# HPM6750 register map
Vendor: HPMICRO; Series: HPM6700/HPM6400; File version: 1.0
HPM6700/HPM6400 device
Registers are 32-bit, access not given, reset 0x0 unless marked. A register's access mark holds for its fields unless they carry their own. Offsets are from the block's base; lines under a group give offsets from that group; [hi:lo] are bit positions; {n}, {i} and the like mark numbered series; 'fields as' and 'values as' point back to an identical list; <NAME> marks a mode.

## Memory map
0xF4040000 IOC size 0xF64 — Input/Output Control
0xF40D8000 PIOC size 0xF64 — Power domain Input/Output Control
0xF5010000 BIOC size 0xF64 — Backup domain Input/Output Control

## IOC — Input/Output Control
Base 0xF4040000
Same registers: PIOC 0xF40D8000, BIOC 0xF5010000
{0x0+8i} pad_a[{i}] (i=0..31) group — Controller for input/output pad A
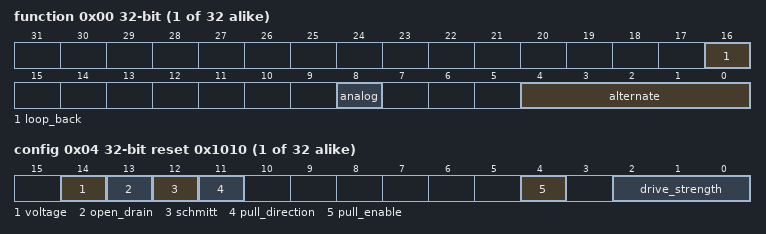
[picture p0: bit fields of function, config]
  0x00 function — Select function for this pad
    [16] loop_back — Enable loop-back output into input
      1=enable (Function enabled); 0=disable (Function disabled)
    [8] analog — Enable analog feature in pad
      1=enable (Function enabled); 0=disable (Function disabled)
    [4:0] alternate — Select alternate function for this pad
  0x04 config reset 0x1010 — Configurate pad settings
    [14] voltage — Select pin voltage; only effective to high speed pads
      0=V3P3 (3.3V); 1=V1P8 (1.8V)
    [13] open_drain — Enable or disable open-drain output
      1=enable (Function enabled); 0=disable (Function disabled)
    [12] schmitt — schmitt trigger enable, only avaiable in high-speed IO
      1=enable (Function enabled); 0=disable (Function disabled)
    [11] pull_direction — Pull direction on this pad if pull enabled
      0=up (This pad is internally pulled up); 1=down (This pad is internally pulled down)
    [4] pull_enable — Enable internal pull on this pin
      1=enable (Function enabled); 0=disable (Function disabled)
    [2:0] drive_strength — Pad drive strength, differs from pin type and voltage
      0=drive_0 (85.61Ω on 3.3V high speed, 84.07Ω on 1.8V high speed, 4mA on normal pad); 1=drive_1 (61.2Ω on 3.3V high speed, 60.14Ω on 1.8V high speed, 8mA on normal pad); 2=drive_2 (42.88Ω on 3.3V high speed, 42.15Ω on 1.8V high speed, N/A on normal pad); 3=drive_3 (35.76Ω on 3.3V high speed, 35.19Ω on 1.8V high speed, 12mA on normal pad); 7=drive_7 (30.67Ω on 3.3V high speed, 30.2Ω on 1.8V high speed, N/A on normal pad)
0x100 pad_b[%s] group — Controller for input/output pad B
  0x00 function — Select function for this pad
    fields as pad_a[0].function
  0x04 config reset 0x1010 — Configurate pad settings
    fields as pad_a[0].config
0x200 pad_c[%s] group — Controller for input/output pad C
  0x00 function — Select function for this pad
    fields as pad_a[0].function
  0x04 config reset 0x1010 — Configurate pad settings
    fields as pad_a[0].config
0x300 pad_d[%s] group — Controller for input/output pad D
  0x00 function — Select function for this pad
    fields as pad_a[0].function
  0x04 config reset 0x1010 — Configurate pad settings
    fields as pad_a[0].config
0x400 pad_e[%s] group — Controller for input/output pad E
  0x00 function — Select function for this pad
    fields as pad_a[0].function
  0x04 config reset 0x1010 — Configurate pad settings
    fields as pad_a[0].config
{0x500+8i} pad_f[{i}] (i=0..10) group — Controller for input/output pad F
  0x00 function — Select function for this pad
    fields as pad_a[0].function
  0x04 config reset 0x1010 — Configurate pad settings
    fields as pad_a[0].config
{0xD00+8i} pad_x[{i}] (i=0..11) group — Controller for input/output pad X
  0x00 function — Select function for this pad
    fields as pad_a[0].function
  0x04 config reset 0x1010 — Configurate pad settings
    fields as pad_a[0].config
{0xE00+8i} pad_y[{i}] (i=0..11) group — Controller for input/output pad Y
  0x00 function — Select function for this pad
    fields as pad_a[0].function
  0x04 config reset 0x1010 — Configurate pad settings
    fields as pad_a[0].config
{0xF00+8i} pad_z[{i}] (i=0..11) group — Controller for input/output pad Z
  0x00 function — Select function for this pad
    fields as pad_a[0].function
  0x04 config reset 0x1010 — Configurate pad settings
    fields as pad_a[0].config

## Licence text in the file
/* * Copyright (c) 2021-2022 hpmicro * * SPDX-License-Identifier: BSD-3-Clause * */
